# STM32G544 register map
File version: 2.0.0
CPU: CM33 r0p4, little endian, MPU, FPU, 4 interrupt priority bits
Registers are 32-bit, read-write, reset 0x0 unless marked. A register's access mark holds for its fields unless they carry their own. Offsets are from the block's base; [hi:lo] are bit positions; {n}, {i} and the like mark numbered series; 'fields as' and 'values as' point back to an identical list.

## HRTIM1 (part 2 of 7) — HRTIM address block description
Base 0x40010000
Same registers: HRTIM1_S 0x50010000
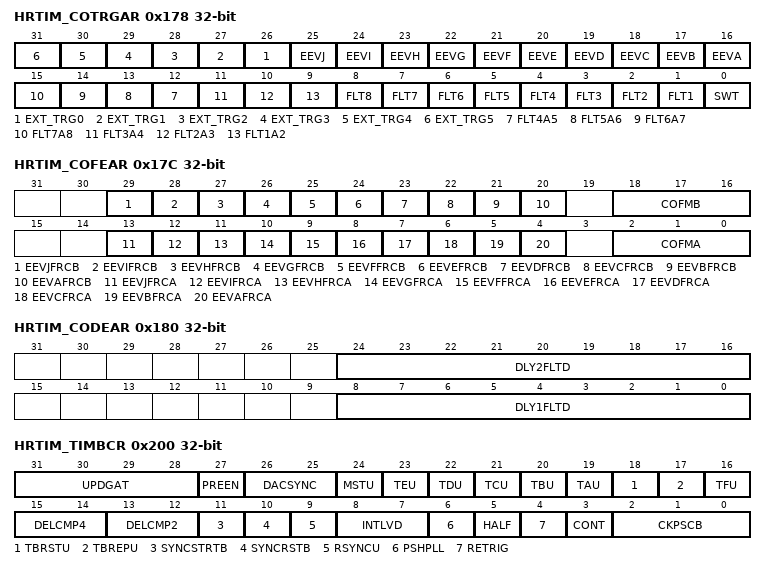
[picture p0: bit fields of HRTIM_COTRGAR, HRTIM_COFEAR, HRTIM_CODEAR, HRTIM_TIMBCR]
0x178 HRTIM_COTRGAR — HRTIM timer A crossbar override trigger register
  [n+26] EXT_TRG{n} (n=0..5) — External trigger {n}
    0=External trigger {n} ignored; 1=External trigger {n} enabled
  [25] EEVJ — EEVJ trigger
    0=EEVJ input trigger ignored; 1=EEVJ input trigger enabled
  [24] EEVI — EEVI trigger
    0=EEVI input trigger ignored; 1=EEVI input trigger enabled
  [23] EEVH — EEVH trigger
    0=EEVH input trigger ignored; 1=EEVH input trigger enabled
  [22] EEVG — EEVG trigger
    0=EEVG input trigger ignored; 1=EEVG input trigger enabled
  [21] EEVF — EEVF trigger
    0=EEVF input trigger ignored; 1=EEVF input trigger enabled
  [20] EEVE — EEVE trigger
    0=EEVE input trigger ignored; 1=EEVE input trigger enabled
  [19] EEVD — EEVD trigger
    0=EEVD input trigger ignored; 1=EEVD input trigger enabled
  [18] EEVC — EEVC trigger
    0=EEVC input trigger ignored; 1=EEVC input trigger enabled
  [17] EEVB — EEVB trigger
    0=EEVB input trigger ignored; 1=EEVB input trigger enabled
  [16] EEVA — EEVA trigger
    0=EEVA input trigger ignored; 1=EEVA input trigger enabled
  [n+8] FLT{n}A{n+1} (n=4..7) — FLT{n}A{n+1} trigger
    0=(Fault {n} AND Fault {n+1}) trigger ignored; 1=(Fault {n} AND Fault {n+1}) trigger enabled
  [11] FLT3A4 — FLT2A3 trigger
    0=(Fault 3 AND Fault 4) trigger ignored; 1=(Fault 3 AND Fault 4) trigger enabled
  [10] FLT2A3 — FLT2A3 trigger
    0=(Fault 2 AND Fault 3) trigger ignored; 1=(Fault 2 AND Fault 3) trigger enabled
  [9] FLT1A2 — FLT1A2 trigger
    0=(Fault 1 AND Fault 2) trigger ignored; 1=(Fault 1 AND Fault 2) trigger enabled
  [n] FLT{n} (n=1..8) — FLT{n} trigger
    0=Fault {n} input trigger ignored; 1=Fault {n} input trigger enabled
  [0] SWT — Software trigger
    0=No action; 1=Crossbar override software trigger
0x17C HRTIM_COFEAR — HRTIM timer A crossbar override forcing event register
  [29] EEVJFRCB — External event J forces output B
    0=No action; 1=Output B is forced to the active levelwhen External Event J is active
  [28] EEVIFRCB — External event I forces output B
    0=No action; 1=Output B is forced to the active levelwhen External Event I is active
  [27] EEVHFRCB — External event H forces output B
    0=No action; 1=Output B is forced to the active levelwhen External Event H is active
  [26] EEVGFRCB — External event G forces output B
    0=No action; 1=Output B is forced to the active levelwhen External Event G is active
  [25] EEVFFRCB — External event F forces output B
    0=No action; 1=Output B is forced to the active levelwhen External Event F is active
  [24] EEVEFRCB — External event E forces output B
    0=No action; 1=Output B is forced to active levelwhen External Event E is active
  [23] EEVDFRCB — External event D forces output B
    0=No action; 1=Output B is forced to the active levelwhen External Event D is active
  [22] EEVCFRCB — External event C forces output B
    0=No action; 1=Output B is forced to the active levelwhen External Event C is active
  [21] EEVBFRCB — External event B forces output B
    0=No action; 1=Output B is forced to the active levelwhen External Event B is active
  [20] EEVAFRCB — External event A forces output B
    0=No action; 1=Output B is forced to active levelwhen External Event A is active
  [18:16] COFMB — Crossbar override force mode output B
    0=Delayed 1 fault; 1=Delayed 2 fault; 2=Output B forced to inactive level; 3=Output B forced to active level; 4=Output B forced on events, as defined with EEVAFRCB..EEVJFRCB bits
  [13] EEVJFRCA — External event J forces output A
    0=No action; 1=Output A is forced to the active levelwhen External Event J is active
  [12] EEVIFRCA — External event I forces output A
    0=No action; 1=Output A is forced to the active levelwhen External Event I is active
  [11] EEVHFRCA — External event H forces output A
    0=No action; 1=Output A is forced to the active levelwhen External Event H is active
  [10] EEVGFRCA — External event G forces output A
    0=No action; 1=Output A is forced to the active levelwhen External Event G is active
  [9] EEVFFRCA — External event F forces output A
    0=No action; 1=Output A is forced to the active levelwhen External Event F is active
  [8] EEVEFRCA — External event E forces output A
    0=No action; 1=Output A is forced to active levelwhen External Event E is active
  [7] EEVDFRCA — External event D forces output A
    0=No action; 1=Output A is forced to the active levelwhen External Event D is active
  [6] EEVCFRCA — External event C forces output A
    0=No action; 1=Output A is forced to the active levelwhen External Event C is active
  [5] EEVBFRCA — External event B forces output A
    0=No action; 1=Output A is forced to the active levelwhen External Event B is active
  [4] EEVAFRCA — External event A forces output A
    0=No action; 1=Output A is forced to active levelwhen External Event A is active
  [2:0] COFMA — Crossbar override force mode output A
    0=Delayed 1 fault; 1=Delayed 2 fault; 2=Output A forced to inactive level; 3=Output A forced to active level; 4=Output A forced on events, as defined with EEVAFRCA..EEVJFRCA bits
0x180 HRTIM_CODEAR — HRTIM timer A crossbar override delayed fault event register
  [24:16] DLY2FLTD — Delayed 2 Fault duration
  [8:0] DLY1FLTD — Delayed 1 Fault duration
0x200 HRTIM_TIMBCR — HRTIM timer B control register
  [31:28] UPDGAT — Update gating
    0=The update occurs independently from the DMA burst transfer; 1=The update occurs when the DMA burst transfer is completed; 2=The update occurs on the update event following the DMA burst transfer completion; 3=The update occurs on a rising edge on hrtim_upd_en1; 4=The update occurs on a rising edge on hrtim_upd_en2; 5=The update occurs on a rising edge on hrtim_upd_en3; 6=The update occurs on the update event following a rising edge on hrtim_upd_en1; 7=The update occurs on the update event following a rising edge on hrtim_upd_en2; 8=The update occurs on the update event following a rising edge on hrtim_upd_en3
  [27] PREEN — Preload enable
    0=Preload disabled: the write access is directly done into the active register; 1=Preload enabled: the write access is done into the preload register
  [26:25] DACSYNC — DAC synchronization
    0=No DAC trigger generated; 1=Trigger generated on hrtim_dac_trg1; 2=Trigger generated on hrtim_dac_trg2; 3=Trigger generated on hrtim_dac_trg3
  [24] MSTU — Master timer update
    0=Update by master timer disabled; 1=Update by master timer enabled
  [23] TEU — Timer E update
    0=Update by timer E disabled; 1=Update by timer E enabled
  [22] TDU — Timer D update
    0=Update by timer D disabled; 1=Update by timer D enabled
  [21] TCU — Timer C update
    0=Update by timer C disabled; 1=Update by timer C enabled
  [20] TBU — Timer B update
    0=Update by timer B disabled; 1=Update by timer B enabled
  [19] TAU — Timer A update
    0=Update by timer A disabled; 1=Update by timer A enabled
  [18] TBRSTU — Timer x reset update
    0=Update by timer x reset / roll-over disabled; 1=Update by timer x reset / roll-over enabled
  [17] TBREPU — Timer x repetition update
    0=Update on repetition disabled; 1=Update on repetition enabled
  [16] TFU — Timer F update
    0=Update by timer F disabled; 1=Update by timer F enabled
  [15:14] DELCMP4 — CMP4 auto-delayed mode
    0=CMP4 register is always active (standard compare mode); 1=CMP4 value is recomputed and is active following a capture 2 event; 2=CMP4 value is recomputed and is active following a capture 2 event, or is recomputed and active after Compare 1 match (timeout function if capture 2 event is missing); 3=CMP4 value is recomputed and is active following a capture 2 event, or is recomputed and active after Compare 3 match (timeout function if capture event is missing)
  [13:12] DELCMP2 — CMP2 auto-delayed mode
    0=CMP2 register is always active (standard compare mode); 1=CMP2 value is recomputed and is active following a capture 1 event; 2=CMP2 value is recomputed and is active following a capture 1 event, or is recomputed and active after compare 1 match (timeout function if capture event is missing); 3=CMP2 value is recomputed and is active following a capture 1 event, or is recomputed and active after compare 3 match (timeout function if capture event is missing)
  [11] SYNCSTRTB — Synchronization starts timer x
    0=No effect on timer x; 1=A synchronization input event starts the timer x
  [10] SYNCRSTB — Synchronization resets timer x
    0=No effect on timer x; 1=A synchronization input event resets the timer x
  [9] RSYNCU — Re-synchronized update
    0=The update coming from adjacent timers (when MSTU, TAU, TBU, TCU, TDU, TEU, TFU bit is set) or from a software update (TxSWU bit) is taken into account immediately; 1=The update coming from adjacent timers (when MSTU, TAU, TBU, TCU, TDU, TEU, TFU bit is set) or from a software update (TxSWU bit) is taken into account on the following reset/roll-over event
  [8:7] INTLVD — Interleaved mode
    0=Interleaved mode disabled; 1=Triple interleaved mode: when HRTIM_PERxR register is written, the HRTIM_CMP1xR active register is automatically updated with HRTIM_PERxR/3 value, and the HRTIM_CMP2xR active register is automatically updated with 2x (HRTIM_PERxR/3) value; 2=Quad interleaved mode: when HRTIM_PERxR register is written, the HRTIM_CMP1xR active register is automatically updated with HRTIM_PERxR/4 value, the HRTIM_CMP2xR active register is automatically updated with HRTIM_PERxR/2 value and the HRTIM_CMP3xR active register is automatically updated with 3x (HRTIM_PERxR/4) value; 3=Interleaved mode disabled
  [6] PSHPLL — Push-pull mode enable
    0=Push-pull mode disabled; 1=Push-pull mode enabled
  [5] HALF — Half mode enable
    0=Half mode disabled; 1=Half mode enabled
  [4] RETRIG — Re-triggerable mode
    0=The timer is not re-triggerable: a counter reset is done if the counter is stopped (period elapsed in single-shot mode or counter stopped in continuous mode); 1=The timer is re-triggerable: a counter reset is done whatever the counter state
  [3] CONT — Continuous mode
    0=The timer operates in single-shot mode and stops when it reaches TIMxPER value; 1=The timer operates in continuous mode and rolls over to zero when it reaches TIMxPER value
  [2:0] CKPSCB — HRTIM timer x clock prescaler
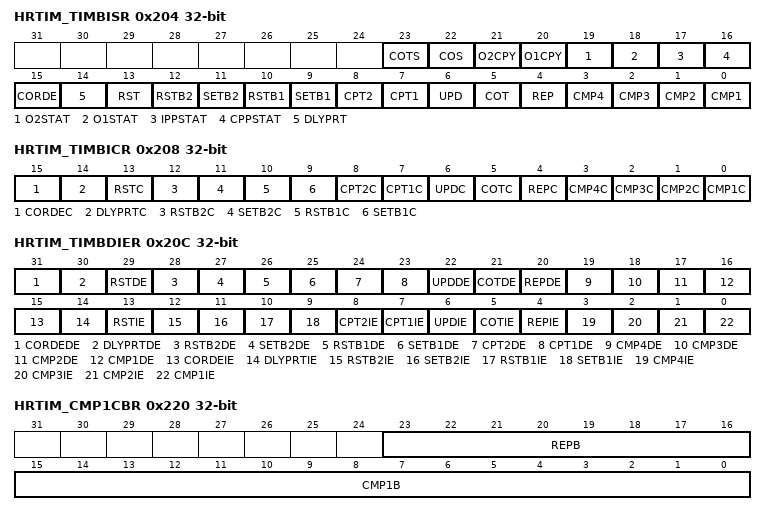
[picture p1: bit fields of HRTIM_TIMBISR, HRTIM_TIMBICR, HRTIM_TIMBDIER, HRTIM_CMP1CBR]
0x204 HRTIM_TIMBISR ro — HRTIM timer B interrupt status register
  [23] COTS — Crossbar Override Trigger status
    0=Crossbar Override trigger is inactive; 1=Crossbar Override trigger is active
  [22] COS — Crossbar Override status
    0=Crossbar Override is inactive (crossbar is active); 1=Crossbar Override is active
  [21] O2CPY — Output 2 copy
    0=Output 2 is inactive; 1=Output 2 is active
  [20] O1CPY — Output 1 copy
    0=Output 1 is inactive; 1=Output 1 is active
  [19] O2STAT — Output 2 status
    0=Output 2 was inactive; 1=Output 2 was active
  [18] O1STAT — Output 1 status
    0=Output 1 was inactive; 1=Output 1 was active
  [17] IPPSTAT — Idle push-pull Status
    0=Protection occurred when the output 1 was active and output 2 forced inactive; 1=Protection occurred when the output 2 was active and output 1 forced inactive
  [16] CPPSTAT — Current push-pull status
    0=Signal applied on output 1 and output 2 forced inactive; 1=Signal applied on output 2 and output 1 forced inactive
  [15] CORDE — Crossbar Override Rearm Delay Elapsed flag
    0=No Crossbar override rearm delay elapsed interrupt occurred; 1=Crossbar override rearm delay elapsed interrupt occurred
  [14] DLYPRT — Delayed protection flag
    0=No delayed protection interrupt occurred; 1=Delayed Idle or balanced Idle mode entry occurred
  [13] RST — Reset and/or roll-over interrupt flag
    0=No TIMx counter reset/roll-over interrupt occurred; 1=TIMX counter reset/roll-over interrupt occurred
  [12] RSTB2 — Output 2 reset interrupt flag timer x
  [11] SETB2 — Output 2 set interrupt flag timer x
  [10] RSTB1 — Output 1 reset interrupt flag timer x
    0=No Tx1 output reset interrupt occurred; 1=Tx1 output reset interrupt occurred
  [9] SETB1 — Output 1 set interrupt flag timer x
    0=No Tx1 output set interrupt occurred; 1=Tx1 output set interrupt occurred
  [8] CPT2 — Capture 2 interrupt flag
  [7] CPT1 — Capture 1 interrupt flag
    0=No timer x capture 1 interrupt occurred; 1=Timer x capture 1 interrupt occurred
  [6] UPD — Update interrupt flag
    0=No timer x update interrupt occurred; 1=Timer x update interrupt occurred
  [5] COT — Crossbar Override Trigger flag
    0=No Crossbar override trigger interrupt occurred; 1=Crossbar override trigger interrupt occurred
  [4] REP — Repetition interrupt flag
    0=No timer x repetition interrupt occurred; 1=Timer x repetition interrupt occurred
  [3] CMP4 — Compare 4 interrupt flag
  [2] CMP3 — Compare 3 interrupt flag
  [1] CMP2 — Compare 2 interrupt flag
  [0] CMP1 — Compare 1 interrupt flag
    0=No compare 1 interrupt occurred; 1=Compare 1 interrupt occurred
0x208 HRTIM_TIMBICR wo — HRTIM timer B interrupt clear register
  [15] CORDEC — Crossbar Override Rearm Delay Elapsed flag clear
  [14] DLYPRTC — Delayed protection flag clear
  [13] RSTC — Reset interrupt flag clear
  [12] RSTB2C — Output 2 reset flag clear timer x
  [11] SETB2C — Output 2 set flag clear timer x
  [10] RSTB1C — Output 1 reset flag clear timer x
  [9] SETB1C — Output 1 set flag clear timer x
  [8] CPT2C — Capture 2 interrupt flag clear
  [7] CPT1C — Capture 1 interrupt flag clear
  [6] UPDC — Update interrupt flag clear
  [5] COTC — Crossbar Override Trigger flag clear
  [4] REPC — Repetition interrupt flag clear
  [n-1] CMP{n}C (n=1..4) — Compare {n} interrupt flag clear
0x20C HRTIM_TIMBDIER — HRTIM timer B DMA interrupt enable register
  [31] CORDEDE — Crossbar override rearm delay elapsed DMA request enable
    0=Crossbar override rearm delay elapsed DMA request disabled; 1=Crossbar override rearm delay elapsed DMA request enabled
  [30] DLYPRTDE — Delayed protection DMA request enable
    0=Delayed protection DMA request disabled; 1=Delayed protection DMA request enabled
  [29] RSTDE — Reset/roll-over DMA request enable
    0=Timer x counter reset/roll-over DMA request disabled; 1=Timer x counter reset/roll-over DMA request enabled
  [28] RSTB2DE — Output 2 reset DMA request enable timer x
  [27] SETB2DE — Output 2 set DMA request enable timer x
  [26] RSTB1DE — Output 1 reset DMA request enable timer x
    0=Tx1 output reset DMA request disabled; 1=Tx1 output reset DMA request enabled
  [25] SETB1DE — Output 1 set DMA request enable timer x
    0=Tx1 output set DMA request disabled; 1=Tx1 output set DMA request enabled
  [24] CPT2DE — Capture 2 DMA request enable
  [23] CPT1DE — Capture 1 DMA request enable
    0=Capture 1 DMA request disabled; 1=Capture 1 DMA request enabled
  [22] UPDDE — Update DMA request enable
    0=Update DMA request disabled; 1=Update DMA request enabled
  [21] COTDE — Crossbar Override Trigger DMA request enable
    0=Crossbar Override Trigger DMA request disabled; 1=Crossbar Override Trigger DMA request enabled
  [20] REPDE — Repetition DMA request enable
    0=Repetition DMA request disabled; 1=Repetition DMA request enabled
  [19] CMP4DE — Compare 4 DMA request enable
  [18] CMP3DE — Compare 3 DMA request enable
  [17] CMP2DE — Compare 2 DMA request enable
  [16] CMP1DE — Compare 1 DMA request enable
    0=Compare 1 DMA request disabled; 1=Compare 1 DMA request enabled
  [15] CORDEIE — Crossbar override rearm delay elapsed interrupt enable
    0=Crossbar override rearm delay elapsed interrupts disabled; 1=Crossbar override rearm delay elapsed interrupts enabled
  [14] DLYPRTIE — Delayed protection interrupt enable
    0=Delayed protection interrupts disabled; 1=Delayed protection interrupts enabled
  [13] RSTIE — Reset/roll-over interrupt enable
    0=Timer x counter reset/roll-over interrupt disabled; 1=Timer x counter reset/roll-over interrupt enabled
  [12] RSTB2IE — Output 2 reset interrupt enable timer x
  [11] SETB2IE — Output 2 set interrupt enable timer x
  [10] RSTB1IE — Output 1 reset interrupt enable timer x
    0=Tx1 output reset interrupts disabled; 1=Tx1 output reset interrupts enabled
  [9] SETB1IE — Output 1 set interrupt enable timer x
    0=Tx1 output set interrupts disabled; 1=Tx1 output set interrupts enabled
  [8] CPT2IE — Capture interrupt enable
  [7] CPT1IE — Capture interrupt enable
    0=Capture 1 interrupts disabled; 1=Capture 1 interrupts enabled
  [6] UPDIE — Update interrupt enable
    0=Update interrupts disabled; 1=Update interrupts enabled
  [5] COTIE — Crossbar Override Trigger interrupt enable
    0=Crossbar Override Trigger interrupts disabled; 1=Crossbar Override Trigger enabled
  [4] REPIE — Repetition interrupt enable
    0=Repetition interrupts disabled; 1=Repetition interrupts enabled
  [3] CMP4IE — Compare 4 interrupt enable
  [2] CMP3IE — Compare 3 interrupt enable
  [1] CMP2IE — Compare 2 interrupt enable
  [0] CMP1IE — Compare 1 interrupt enable
    0=Compare 1 interrupt disabled; 1=Compare 1 interrupt enabled
0x210 HRTIM_CNTBR — HRTIM timer B counter register
  [15:0] CNTB — Timer x counter value
0x214 HRTIM_PERBR reset 0xFFDF — HRTIM timer B period register
  [15:0] PERB — Timer x period value
0x218 HRTIM_REPBR — HRTIM timer B repetition register
  [7:0] REPB — Timer x repetition period value
0x21C HRTIM_CMP1BR — HRTIM timer B compare 1 register
  [15:0] CMP1B — Timer x compare 1 value
0x220 HRTIM_CMP1CBR — HRTIM timer B compare 1 compound register
  [23:16] REPB — Timer x repetition value aliased from HRTIM_REPx register
  [15:0] CMP1B — Timer x compare 1 value
{0x21C+4i} HRTIM_CMP{i}BR (i=2..4) — HRTIM timer B compare {i} register
  [15:0] CMP{i}B — Timer x compare {i} value
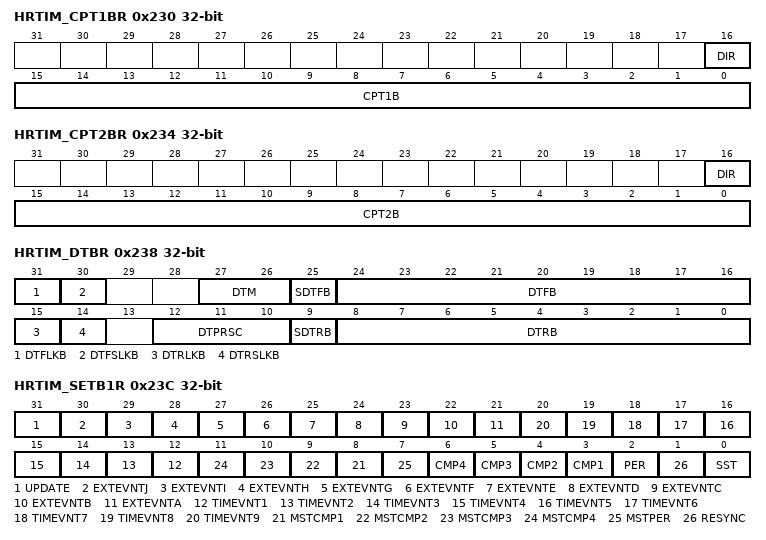
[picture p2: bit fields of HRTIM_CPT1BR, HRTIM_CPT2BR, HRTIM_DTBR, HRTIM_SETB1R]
0x230 HRTIM_CPT1BR ro — HRTIM timer B capture 1 register
  [16] DIR — Timer x capture 1 direction status
    0=timer is up-counting; 1=timer is down-counting
  [15:0] CPT1B — Timer x capture 1 value
0x234 HRTIM_CPT2BR ro — HRTIM timer B capture 2 register
  [16] DIR — Timer x capture 1 direction status
    0=timer is up-counting; 1=timer is down-counting
  [15:0] CPT2B — Timer x capture 2 value
0x238 HRTIM_DTBR rw-once — HRTIM timer B deadtime register
  [31] DTFLKB — Deadtime falling lock timer x
    0=Deadtime falling value and sign is writable; 1=Deadtime falling value and sign is read-only
  [30] DTFSLKB — Deadtime falling sign lock timer x
    0=Deadtime falling sign is writable; 1=Deadtime falling sign is read-only
  [27:26] DTM rw — Deadtime mode
    0=Deadtime complementary mode; 1=Deadtime insertion mode; 2=Deadtime insertion and disarm mode
  [25] SDTFB rw — Sign deadtime falling value timer x
    0=Positive deadtime on falling edge; 1=Negative deadtime on falling edge
  [24:16] DTFB rw — Deadtime falling value timer x
  [15] DTRLKB — Deadtime rising lock timer x
    0=Deadtime rising value and sign is writable; 1=Deadtime rising value and sign is read-only
  [14] DTRSLKB — Deadtime rising sign lock timer x
    0=Deadtime rising sign is writable; 1=Deadtime rising sign is read-only
  [12:10] DTPRSC rw — Deadtime prescaler
  [9] SDTRB rw — Sign deadtime rising value timer x
    0=Positive deadtime on rising edge; 1=Negative deadtime on rising edge
  [8:0] DTRB rw — Deadtime rising value timer x
0x23C HRTIM_SETB1R — HRTIM timer B output 1 set register
  [31] UPDATE — Registers update (transfer from preload register to active register)
  [30] EXTEVNTJ — External event J
  [29] EXTEVNTI — External event I
  [28] EXTEVNTH — External event H
  [27] EXTEVNTG — External event G
  [26] EXTEVNTF — External event F
  [25] EXTEVNTE — External event E
  [24] EXTEVNTD — External event D
  [23] EXTEVNTC — External event C
  [22] EXTEVNTB — External event B
  [21] EXTEVNTA — External event A
  [n+11] TIMEVNT{n} (n=1..9) — Timer event {n}
  [n+7] MSTCMP{n} (n=1..4) — Master compare {n}
  [7] MSTPER — Master period
  [n+2] CMP{n} (n=1..4) — Timer x compare {n}
  [2] PER — Timer x period
  [1] RESYNC — Timer A resynchronization
  [0] SST — Software set trigger
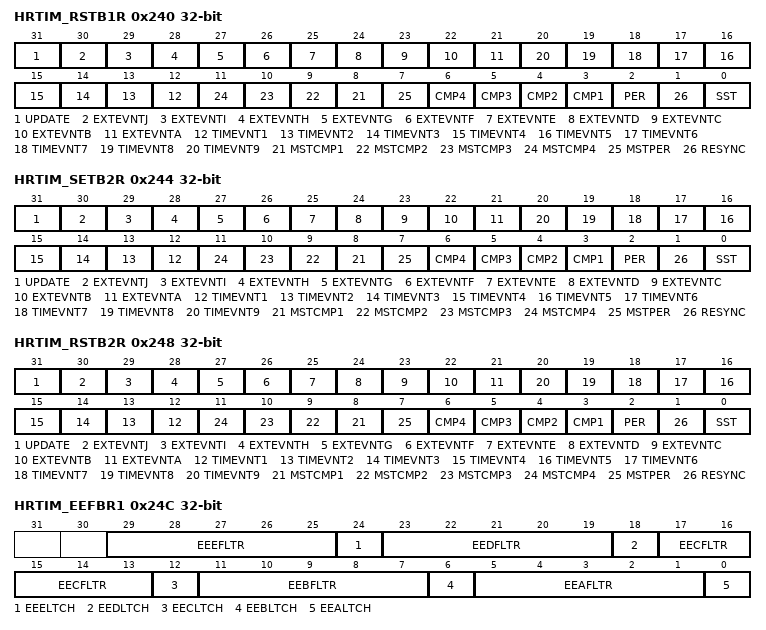
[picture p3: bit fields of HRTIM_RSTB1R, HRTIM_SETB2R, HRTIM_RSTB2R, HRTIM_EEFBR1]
0x240 HRTIM_RSTB1R — HRTIM timer B output 1 reset register
  fields as HRTIM_SETB1R
0x244 HRTIM_SETB2R — HRTIM timer B output 2 set register
  fields as HRTIM_SETB1R
0x248 HRTIM_RSTB2R — HRTIM timer B output 2 reset register
  fields as HRTIM_SETB1R
0x24C HRTIM_EEFBR1 — HRTIM timer B external event filtering register 1
  [29:25] EEEFLTR — External event E filter
  [24] EEELTCH — External event E latch
  [23:19] EEDFLTR — External event D filter
  [18] EEDLTCH — External event D latch
  [17:13] EECFLTR — External event C filter
  [12] EECLTCH — External event C latch
  [11:7] EEBFLTR — External event B filter
  [6] EEBLTCH — External event B latch
  [5:1] EEAFLTR — External event A filter
    0=No filtering; 1=Blanking from counter reset/roll-over to compare 1; 2=Blanking from counter reset/roll-over to compare 2 in up-counting mode (UDM bit reset); 3=Blanking from counter reset/roll-over to compare 3; 4=Blanking from counter reset/roll-over to compare 4 in up-counting mode (UDM bit reset); 13=Windowing from counter reset/roll-over to compare 2 in up-counting mode (UDM bit reset); 14=Windowing from counter reset/roll-over to compare 3 in up-counting mode (UDM bit reset); 15=Windowing from another timing unit: TIMWIN source (see Table233 for details) in up-counting mode (UDM bit reset); 16=Blanking from compare 1 to counter reset/roll-over (UDM bit reset).In up-down counting mode (UDM bit set): blanking from compare 1 during down-counting to compare 2 during the following up-counting phase; 17=Blanking from compare 2 to counter reset/roll-over (UDM bit reset).In up-down counting mode (UDM bit set): blanking from CMP1 (down-counting) to CMP2 (down-counting); 18=Blanking from compare 1 to compare 2 (UDM bit reset). In up-down counting mode (UDM bit set): blanking from CMP1 (up-counting) to CMP2 (down-counting.; 19=Blanking from compare 3 to compare 4 (UDM bit reset). In up-down counting mode (UDM bit set): blanking from CMP3 (up-counting) to CMP4 (down-counting).; 20=Windowing from compare 1 to counter reset/roll-over. In up-down counting mode (UDM bit set), the reset/roll-over event is conditioned to the ROM[1:0] bit field setting; 21=Windowing from compare 2 to counter reset/roll-over. In up-down counting mode (UDM bit set), the reset/roll-over event is conditioned to the ROM[1:0] bit field setting; 22=Windowing from compare 1 to compare 2 (UDM bit reset). In up-down counting mode (UDM bit set): windowing from CMP1 (up-counting) to CMP2 (down-counting).; 23=Windowing from compare 3 to compare 4 (UDM bit reset). In up-down counting mode (UDM bit set): windowing from compare 3 during down-counting to compare 4 during the following up-counting phase; 24=TIMWIN2 source (see Table233 for details). In up-down counting mode (UDM bit set), the reset/roll-over event is conditioned to the ROM[1:0] bit field setting; 25=TIMWIN3 source (see Table233 for details); 26=Blanking from Period Event to Compare 1 In up-down counting mode (UDM bit set), the reset/roll-over event is conditioned to the ROM[1:0] bit field setting; 27=Blanking from Period Event to Compare 2 In up-down counting mode (UDM bit set), the reset/roll-over event is conditioned to the ROM[1:0] bit field setting
  [0] EEALTCH — External event A latch
    0=Event A is ignored if it happens during a blank, or passed through during a window; 1=Event A is latched and delayed till the end of the blanking or windowing period
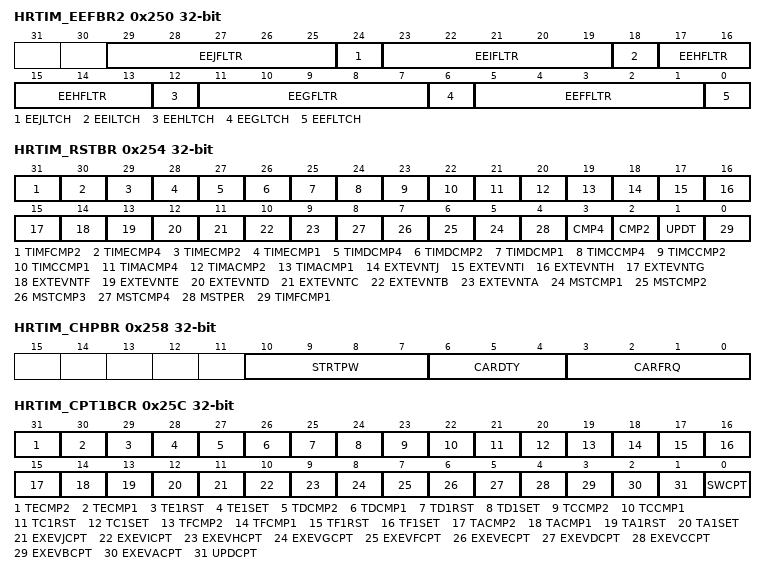
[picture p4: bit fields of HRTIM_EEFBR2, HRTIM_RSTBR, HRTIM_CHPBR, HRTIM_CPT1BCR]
0x250 HRTIM_EEFBR2 — HRTIM timer B external event filtering register 2
  [29:25] EEJFLTR — External event J filter
  [24] EEJLTCH — External event J latch
  [23:19] EEIFLTR — External event I filter
  [18] EEILTCH — External event I latch
  [17:13] EEHFLTR — External event H filter
  [12] EEHLTCH — External event H latch
  [11:7] EEGFLTR — External event G filter
  [6] EEGLTCH — External event G latch
  [5:1] EEFFLTR — External event F filter
  [0] EEFLTCH — External event F latch
0x254 HRTIM_RSTBR — HRTIM timer B reset register
  [31] TIMFCMP2 — Timer F compare 2
  [30] TIMECMP4 — Timer E compare 4
  [29] TIMECMP2 — Timer E compare 2
  [28] TIMECMP1 — Timer E compare 1
  [27] TIMDCMP4 — Timer D compare 4
  [26] TIMDCMP2 — Timer D compare 2
  [25] TIMDCMP1 — Timer D compare 1
  [24] TIMCCMP4 — Timer C compare 4
  [23] TIMCCMP2 — Timer C compare 2
  [22] TIMCCMP1 — Timer C compare 1
  [21] TIMACMP4 — Timer A compare 4
  [20] TIMACMP2 — Timer A compare 2
  [19] TIMACMP1 — Timer A compare 1
  [18] EXTEVNTJ — External event J
  [17] EXTEVNTI — External event I
  [16] EXTEVNTH — External event H
  [15] EXTEVNTG — External event G
  [14] EXTEVNTF — External event F
  [13] EXTEVNTE — External event E
  [12] EXTEVNTD — External event D
  [11] EXTEVNTC — External event C
  [10] EXTEVNTB — External event B
  [9] EXTEVNTA — External event A
  [n+4] MSTCMP{n} (n=1..4) — Master compare {n}
  [4] MSTPER — Master timer period
  [3] CMP4 — Timer B compare 4 reset
  [2] CMP2 — Timer B compare 2 reset
  [1] UPDT — Timer B update reset
  [0] TIMFCMP1 — Timer F compare 1
0x258 HRTIM_CHPBR — HRTIM timer B chopper register
  [10:7] STRTPW — Timer x start pulsewidth
    0=64 ns (1/15.63 MHz); 15=1.02 us (16/15.63 MHz)
  [6:4] CARDTY — Timer x chopper duty cycle value
    0=0/8 (i.e. only 1st pulse is present); 7=7/8
  [3:0] CARFRQ — Timer x carrier frequency value
    0=15.63 MHz (fless thansub>HRTIMless than/sub>/ 16); 15=976.6 kHz (fless thansub>HRTIMless than/sub> / 256)
0x25C HRTIM_CPT1BCR — HRTIM timer B capture 1 control register
  [31] TECMP2 — Timer E compare 2
  [30] TECMP1 — Timer E compare 1
  [29] TE1RST — Timer E output 1 reset
  [28] TE1SET — Timer E output 1 set
  [27] TDCMP2 — Timer D compare 2
  [26] TDCMP1 — Timer D compare 1
  [25] TD1RST — Timer D output 1 reset
  [24] TD1SET — Timer D output 1 set
  [23] TCCMP2 — Timer C compare 2
  [22] TCCMP1 — Timer C compare 1
  [21] TC1RST — Timer C output 1 reset
  [20] TC1SET — Timer C output 1 set
  [19] TFCMP2 — Timer F compare 2
  [18] TFCMP1 — Timer F compare 1
  [17] TF1RST — Timer F output 1 reset
  [16] TF1SET — Timer F output 1 set
  [15] TACMP2 — Timer A compare 2
    0=No action; 1=Timer A compare 2 triggers capture 1
  [14] TACMP1 — Timer A compare 1
    0=No action; 1=Timer A compare 1 triggers capture1
  [13] TA1RST — Timer B output 1 reset
    0=No action; 1=Capture 1 is triggered by TA1 output active to inactive transition
  [12] TA1SET — Timer B output 1 set
    0=No action; 1=Capture 1 is triggered by TA1 output inactive to active transition
  [11] EXEVJCPT — External event J capture
  [10] EXEVICPT — External event I capture
  [9] EXEVHCPT — External event H capture
  [8] EXEVGCPT — External event G capture
  [7] EXEVFCPT — External event F capture
  [6] EXEVECPT — External event E capture
  [5] EXEVDCPT — External event D capture
  [4] EXEVCCPT — External event C capture
  [3] EXEVBCPT — External event B capture
  [2] EXEVACPT — External event A capture
    0=No action; 1=The external event A triggers the capture 1
  [1] UPDCPT — Update capture
    0=No action; 1=The update event triggers the capture 1
  [0] SWCPT — Software capture
    0=No action; 1=This bit forces the capture 1 by software. This bit is set only, reset by hardware.
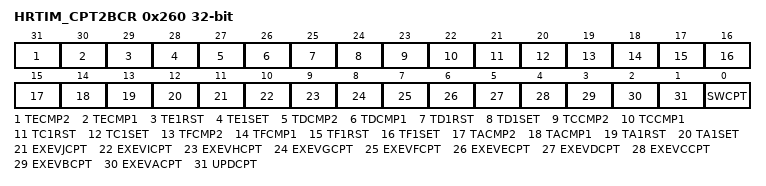
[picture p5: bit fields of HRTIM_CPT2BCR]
0x260 HRTIM_CPT2BCR — HRTIM timer B capture 2 control register
  [31] TECMP2 — Timer E compare 2
  [30] TECMP1 — Timer E compare 1
  [29] TE1RST — Timer E output 1 reset
  [28] TE1SET — Timer E output 1 set
  [27] TDCMP2 — Timer D compare 2
  [26] TDCMP1 — Timer D compare 1
  [25] TD1RST — Timer D output 1 reset
  [24] TD1SET — Timer D output 1 set
  [23] TCCMP2 — Timer C compare 2
  [22] TCCMP1 — Timer C compare 1
  [21] TC1RST — Timer C output 1 reset
  [20] TC1SET — Timer C output 1 set
  [19] TFCMP2 — Timer F compare 2
  [18] TFCMP1 — Timer F compare 1
  [17] TF1RST — Timer F output 1 reset
  [16] TF1SET — Timer F output 1 set
  [15] TACMP2 — Timer A compare 2
    0=No action; 1=Timer A compare 2 triggers capture 2
  [14] TACMP1 — Timer A compare 1
    0=No action; 1=Timer A compare 1 triggers capture 2
  [13] TA1RST — Timer B output 1 reset
    0=No action; 1=Capture 2 is triggered by TA1 output active to inactive transition
  [12] TA1SET — Timer B output 1 set
    0=No action; 1=Capture 2 is triggered by TA1 output inactive to active transition
  [11] EXEVJCPT — External event J capture
  [10] EXEVICPT — External event I capture
  [9] EXEVHCPT — External event H capture
  [8] EXEVGCPT — External event G capture
  [7] EXEVFCPT — External event F capture
  [6] EXEVECPT — External event E capture
  [5] EXEVDCPT — External event D capture
  [4] EXEVCCPT — External event C capture
  [3] EXEVBCPT — External event B capture
  [2] EXEVACPT — External event A capture
    0=No action; 1=The external event A triggers the capture 2
  [1] UPDCPT — Update capture
    0=No action; 1=The update event triggers the capture 2
  [0] SWCPT — Software capture
    0=No action; 1=This bit forces the capture 2 by software. This bit is set only, reset by hardware.
